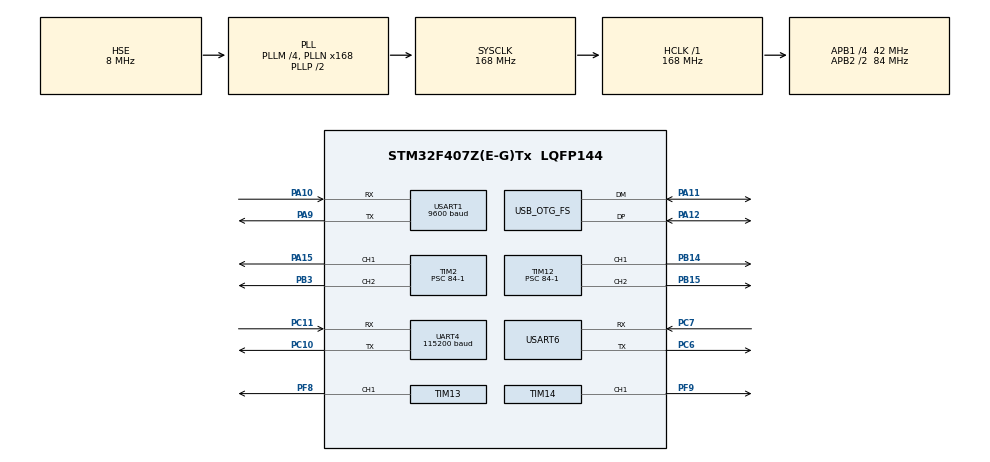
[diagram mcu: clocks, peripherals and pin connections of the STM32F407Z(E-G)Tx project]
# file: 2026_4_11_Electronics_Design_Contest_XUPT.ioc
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Mcu.Family=STM32F4
Mcu.Name=STM32F407Z(E-G)Tx
Mcu.Package=LQFP144
NVIC.OTG_FS_IRQn=true\:0\:0\:false\:false\:true\:false\:true\:true
NVIC.PriorityGroup=NVIC_PRIORITYGROUP_4
NVIC.TIM1_TRG_COM_TIM11_IRQn=true\:0\:0\:false\:false\:true\:true\:true\:true
NVIC.UART4_IRQn=true\:0\:0\:false\:false\:true\:true\:true\:true
NVIC.USART1_IRQn=true\:0\:0\:false\:false\:true\:true\:true\:true
NVIC.USART6_IRQn=true\:0\:0\:false\:false\:true\:true\:true\:true
PA10.Mode=Asynchronous
PA10.Signal=USART1_RX
PA11.Mode=Device_Only
PA11.Signal=USB_OTG_FS_DM
PA12.Mode=Device_Only
PA12.Signal=USB_OTG_FS_DP
PA13.Mode=Serial_Wire
PA13.Signal=SYS_JTMS-SWDIO
PA14.Mode=Serial_Wire
PA14.Signal=SYS_JTCK-SWCLK
PA15.Signal=S_TIM2_CH1_ETR
PA9.Mode=Asynchronous
PA9.Signal=USART1_TX
PB14.Signal=S_TIM12_CH1
PB15.Signal=S_TIM12_CH2
PB3.Signal=S_TIM2_CH2
PC10.Mode=Asynchronous
PC10.Signal=UART4_TX
PC11.Mode=Asynchronous
PC11.Signal=UART4_RX
PC6.Mode=Asynchronous
PC6.Signal=USART6_TX
PC7.Mode=Asynchronous
PC7.Signal=USART6_RX
PF8.Signal=S_TIM13_CH1
PF9.Signal=S_TIM14_CH1
PH0-OSC_IN.Mode=HSE-External-Oscillator
PH0-OSC_IN.Signal=RCC_OSC_IN
PH1-OSC_OUT.Mode=HSE-External-Oscillator
PH1-OSC_OUT.Signal=RCC_OSC_OUT
ProjectManager.HeapSize=0x200
ProjectManager.StackSize=0x400
ProjectManager.TargetToolchain=MDK-ARM V5.32
RCC.48MHZClocksFreq_Value=48000000
RCC.AHBFreq_Value=168000000
RCC.APB1CLKDivider=RCC_HCLK_DIV4
RCC.APB1Freq_Value=42000000
RCC.APB1TimFreq_Value=84000000
RCC.APB2CLKDivider=RCC_HCLK_DIV2
RCC.APB2Freq_Value=84000000
RCC.APB2TimFreq_Value=168000000
RCC.CortexFreq_Value=168000000
RCC.HCLKFreq_Value=168000000
RCC.HSE_VALUE=8000000
RCC.HSI_VALUE=16000000
RCC.LSE_VALUE=32768
RCC.PLLM=4
RCC.PLLN=168
RCC.PLLQ=7
RCC.SYSCLKFreq_VALUE=168000000
RCC.SYSCLKSource=RCC_SYSCLKSOURCE_PLLCLK
RCC.VCOOutputFreq_Value=336000000
SH.S_TIM12_CH1.0=TIM12_CH1,PWM Generation1 CH1
SH.S_TIM12_CH2.0=TIM12_CH2,PWM Generation2 CH2
SH.S_TIM13_CH1.0=TIM13_CH1,PWM Generation1 CH1
SH.S_TIM14_CH1.0=TIM14_CH1,PWM Generation1 CH1
SH.S_TIM2_CH1_ETR.0=TIM2_CH1,PWM Generation1 CH1
SH.S_TIM2_CH2.0=TIM2_CH2,PWM Generation2 CH2
TIM11.Period=5000-1
TIM11.Prescaler=168-1
TIM12.AutoReloadPreload=TIM_AUTORELOAD_PRELOAD_ENABLE
TIM12.Channel-PWM\ Generation1\ CH1=TIM_CHANNEL_1
TIM12.Channel-PWM\ Generation2\ CH2=TIM_CHANNEL_2
TIM12.Period=10000-1
TIM12.Prescaler=84-1
TIM12.Pulse-PWM\ Generation1\ CH1=1500
TIM12.Pulse-PWM\ Generation2\ CH2=1500
TIM13.Channel=TIM_CHANNEL_1
TIM13.Period=20000-1 
TIM13.Prescaler=84-1
TIM14.Channel=TIM_CHANNEL_1
TIM14.Period=20000-1
TIM14.Prescaler=84-1
TIM2.Channel-PWM\ Generation1\ CH1=TIM_CHANNEL_1
TIM2.Channel-PWM\ Generation2\ CH2=TIM_CHANNEL_2
TIM2.Period=5000-1
TIM2.Prescaler=84-1
UART4.BaudRate=115200
UART4.VirtualMode=Asynchronous
USART1.BaudRate=9600
USART1.VirtualMode=VM_ASYNC
USART6.VirtualMode=VM_ASYNC
USB_DEVICE.CLASS_NAME_FS=CDC
USB_DEVICE.VirtualMode-CDC_FS=Cdc
USB_DEVICE.VirtualModeFS=Cdc_FS
USB_OTG_FS.VirtualMode=Device_Only
VP_TIM11_VS_ClockSourceINT.Mode=Enable_Timer
VP_TIM13_VS_ClockSourceINT.Mode=Enable_Timer
VP_TIM14_VS_ClockSourceINT.Mode=Enable_Timer
VP_USB_DEVICE_VS_USB_DEVICE_CDC_FS.Mode=CDC_FS
board=custom

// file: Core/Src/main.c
/* USER CODE BEGIN Header */
/**
  ******************************************************************************
  * @file           : main.c
  * @brief          : Main program body
  ******************************************************************************
  * @attention
  *
  * Copyright (c) 2026 STMicroelectronics.
  * All rights reserved.
  *
  * This software is licensed under terms that can be found in the LICENSE file
  * in the root directory of this software component.
  * If no LICENSE file comes with this software, it is provided AS-IS.
  *
  ******************************************************************************
  */
/* USER CODE END Header */
#include "main.h"
#include "tim.h"
#include "usart.h"
#include "usb_device.h"
#include "gpio.h"

/* USER CODE BEGIN Includes */
/* 主循环只保留任务入口，具体控制逻辑和调试逻辑分别放在独立模块中��?*/
#include "vision_control.h"
#include "vision_debug_uart.h"
#include "Servo_device.h"
/* USER CODE END Includes */

void SystemClock_Config(void);

int main(void)
{

  /* MCU Configuration--------------------------------------------------------*/

  /* Reset of all peripherals, Initializes the Flash interface and the Systick. */
  HAL_Init();

  /* Configure the system clock */
  SystemClock_Config();

  /* Initialize all configured peripherals */
  MX_GPIO_Init();
  MX_USB_DEVICE_Init();
  MX_TIM14_Init();
  MX_TIM13_Init();
  MX_TIM12_Init();
  MX_USART1_UART_Init();
  MX_UART4_Init();
  MX_TIM11_Init();
  MX_USART6_UART_Init();
  MX_TIM2_Init();
  /* USER CODE BEGIN 2 */
  if (VisionControl_Init() != BSP_OK)
  {
    Error_Handler();
  }

  if (VisionDebugUart_Init() != BSP_OK)
  {
    Error_Handler();
  }

  int angle_1=90,angle_2=90;
  uint8_t tx_buffer[64];
  /* 串口屏显示、视觉闭环控制、TIM12 调试舵机都已由各自模块内部接管
     因此 main.c 这里只保留任务初始化入口，不再额外做舵机测试写值*/
  /* USER CODE END 2 */

  /* Infinite loop */
  while (1)
  {

    /* USER CODE BEGIN 3 */
    // sprintf(tx_buffer,"n0.val=1\xff\xff\xff");
    // HAL_UART_Transmit(&huart1,(uint8_t*)tx_buffer,strlen(tx_buffer),1000);

    VisionControl_Task();      // 视觉控制任务，负责处理视觉输入、题目状态机和双环控制

    // // 位置
    VisionDebugUart_Task();

    // VisionDebugUart_VelocityTask();

    // Servo_SetAngle(SERVO_TIM2_1,angle_1);
    // Servo_SetAngle(SERVO_TIM2_2,angle_2);

  }
  /* USER CODE END 3 */
}

void SystemClock_Config(void)
{
  RCC_OscInitTypeDef RCC_OscInitStruct = {0};
  RCC_ClkInitTypeDef RCC_ClkInitStruct = {0};

  /** Configure the main internal regulator output voltage
  */
  __HAL_RCC_PWR_CLK_ENABLE();
  __HAL_PWR_VOLTAGESCALING_CONFIG(PWR_REGULATOR_VOLTAGE_SCALE1);

  /** Initializes the RCC Oscillators according to the specified parameters
  * in the RCC_OscInitTypeDef structure.
  */
  RCC_OscInitStruct.OscillatorType = RCC_OSCILLATORTYPE_HSE;
  RCC_OscInitStruct.HSEState = RCC_HSE_ON;
  RCC_OscInitStruct.PLL.PLLState = RCC_PLL_ON;
  RCC_OscInitStruct.PLL.PLLSource = RCC_PLLSOURCE_HSE;
  RCC_OscInitStruct.PLL.PLLM = 4;
  RCC_OscInitStruct.PLL.PLLN = 168;
  RCC_OscInitStruct.PLL.PLLP = RCC_PLLP_DIV2;
  RCC_OscInitStruct.PLL.PLLQ = 7;
  if (HAL_RCC_OscConfig(&RCC_OscInitStruct) != HAL_OK)
  {
    Error_Handler();
  }

  /** Initializes the CPU, AHB and APB buses clocks
  */
  RCC_ClkInitStruct.ClockType = RCC_CLOCKTYPE_HCLK|RCC_CLOCKTYPE_SYSCLK
                              |RCC_CLOCKTYPE_PCLK1|RCC_CLOCKTYPE_PCLK2;
  RCC_ClkInitStruct.SYSCLKSource = RCC_SYSCLKSOURCE_PLLCLK;
  RCC_ClkInitStruct.AHBCLKDivider = RCC_SYSCLK_DIV1;
  RCC_ClkInitStruct.APB1CLKDivider = RCC_HCLK_DIV4;
  RCC_ClkInitStruct.APB2CLKDivider = RCC_HCLK_DIV2;

  if (HAL_RCC_ClockConfig(&RCC_ClkInitStruct, FLASH_LATENCY_5) != HAL_OK)
  {
    Error_Handler();
  }
}

void Error_Handler(void)
{
  __disable_irq();
  while (1)
  {
  }
}
